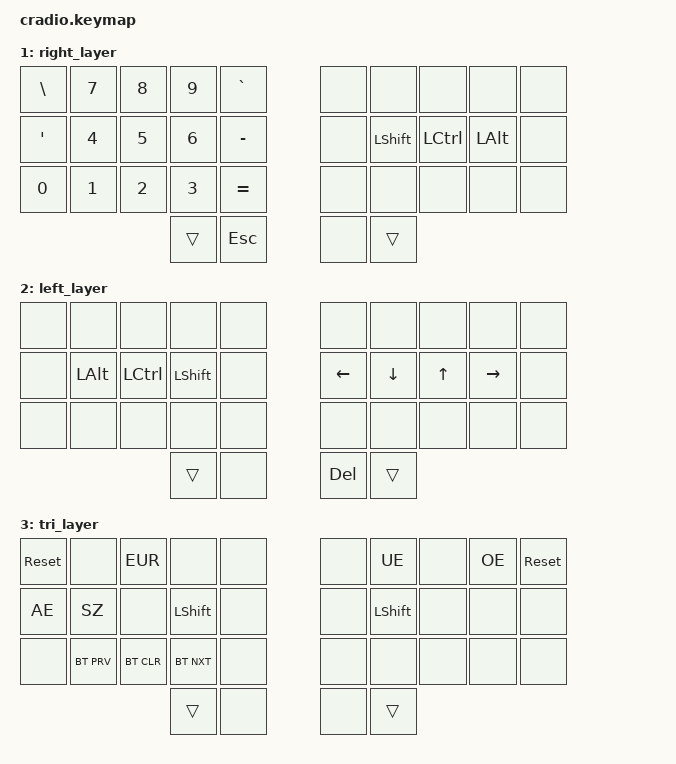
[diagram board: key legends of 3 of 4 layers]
// Copyright (c) 2022 The ZMK Contributors
// SPDX-License-Identifier: MIT

#include <behaviors.dtsi>
#include <dt-bindings/zmk/keys.h>
#include <dt-bindings/zmk/bt.h>

// Home row mods macro
#define HRML(k1,k2,k3) &ht_bl LALT  k1  &ht_bl LCTRL k2  &ht_bl LSHFT k3
#define HRMR(k1,k2,k3) &ht_bl LSHFT k1  &ht_bl LCTRL k2  &ht_bl LALT  k3

#define AE  RA(Q)
#define OE  RA(P)
#define UE  RA(Y)
#define SZ  RA(S)
#define EUR RA(N5)

/ {
    behaviors {
        ht_bl: hold_tap__hold_preferred {
            label = "hold_tap";
            compatible = "zmk,behavior-hold-tap";
            #binding-cells = <2>;
            flavor = "balanced";
            tapping-term-ms = <200>;
            quick-tap-ms = <150>;
            require-prior-idle-ms = <100>;
            bindings = <&kp>, <&kp>;
        };
    };

    combos {
        compatible = "zmk,combos";
        combo_lbrc {
            timeout-ms = <50>;
            key-positions = <10 11>;
            bindings = <&kp LBRC>;
        };
        combo_lbkt {
            timeout-ms = <50>;
            key-positions = <11 12>;
            bindings = <&kp LBKT>;
        };
        combo_lpar {
            timeout-ms = <50>;
            key-positions = <12 13>;
            bindings = <&kp LPAR>;
        };
        combo_rpar {
            timeout-ms = <50>;
            key-positions = <16 17>;
            bindings = <&kp RPAR>;
        };
        combo_rbkt {
            timeout-ms = <50>;
            key-positions = <17 18>;
            bindings = <&kp RBKT>;
        };
        combo_rbrc {
            timeout-ms = <50>;
            key-positions = <18 19>;
            bindings = <&kp RBRC>;
        };
    };

    conditional_layers {
        compatible = "zmk,conditional-layers";
        tri_layer {
            if-layers = <1 2>;
            then-layer = <3>;
        };
    };

    keymap {
        compatible = "zmk,keymap";
        default_layer {
            bindings = <
        //╭──────────┬──────────┬──────────┬──────────┬──────────╮   ╭──────────┬──────────┬──────────┬──────────┬──────────╮
        //│  Q       │  W       │  E       │  R       │  T       │   │  Y       │  U       │  I       │  O       │  P       │
            &kp Q      &kp W      &kp E      &kp R      &kp T          &kp Y      &kp U      &kp I      &kp O      &kp P
        //├──────────┼──────────┼──────────┼──────────┼──────────┤   ├──────────┼──────────┼──────────┼──────────┼──────────┤
        //│  A       │  S       │  D       │  F       │  G       │   │  H       │  J       │  K       │  L       │  ;:      │
            &kp A      HRML(S,    D,         F)         &kp G          &kp H      HRMR(J,    K,         L)         &kp SEMI
        //├──────────┼──────────┼──────────┼──────────┼──────────┤   ├──────────┼──────────┼──────────┼──────────┼──────────┤
        //│  Z       │  X       │  C       │  V       │  B       │   │  N       │  M       │ , <      │ . >      │ / ?      │
            &kp Z      &kp X      &kp C      &kp V      &kp B          &kp N      &kp M      &kp COMMA  &kp DOT    &kp FSLH
        //╰──────────┴──────────┴──────────┼──────────┼──────────┤   ├──────────┼──────────┼──────────┴──────────┴──────────╯
                                             &lt 2 TAB  &kp SPACE      &kp BSPC   &lt 1 ENTER
        //                                 ╰──────────┴──────────╯   ╰──────────┴──────────╯
            >;
        };

        right_layer {
            bindings = <
        //╭──────────┬──────────┬──────────┬──────────┬──────────╮   ╭──────────┬──────────┬──────────┬──────────┬──────────╮
        //│  \|      │  7       │  8       │  9       │  `~      │   │          │          │          │          │          │
            &kp BSLH   &kp N7     &kp N8     &kp N9     &kp GRAVE      &none      &none      &none      &none      &none
        //├──────────┼──────────┼──────────┼──────────┼──────────┤   ├──────────┼──────────┼──────────┼──────────┼──────────┤
        //│  '"      │  4       │  5       │  6       │  -_      │   │          │          │          │          │          │
            &kp SQT    &kp N4     &kp N5     &kp N6     &kp MINUS      &none      &kp LSHFT  &kp LCTRL  &kp LALT   &none
        //├──────────┼──────────┼──────────┼──────────┼──────────┤   ├──────────┼──────────┼──────────┼──────────┼──────────┤
        //│  0       │  1       │  2       │  3       │  =+      │   │          │          │          │          │          │
            &kp N0     &kp N1     &kp N2     &kp N3     &kp EQUAL      &none      &none      &none      &none      &none
        //╰──────────┴──────────┴──────────┼──────────┼──────────┤   ├──────────┼──────────┼──────────┴──────────┴──────────╯
                                             &trans     &kp ESC        &none      &trans
        //                                 ╰──────────┴──────────╯   ╰──────────┴──────────╯
            >;
        };

        left_layer {
            bindings = <
        //╭──────────┬──────────┬──────────┬──────────┬──────────╮   ╭──────────┬──────────┬──────────┬──────────┬──────────╮
        //│          │          │          │          │          │   │          │          │          │          │          │
            &none      &none      &none      &none      &none          &none      &none      &none      &none      &none
        //├──────────┼──────────┼──────────┼──────────┼──────────┤   ├──────────┼──────────┼──────────┼──────────┼──────────┤
        //│          │          │          │          │          │   │  LEFT    │  DOWN    │  UP      │  RIGHT   │          │
            &none      &kp LALT   &kp LCTRL  &kp LSHFT  &none          &kp LEFT   &kp DOWN   &kp UP     &kp RIGHT  &none
        //├──────────┼──────────┼──────────┼──────────┼──────────┤   ├──────────┼──────────┼──────────┼──────────┼──────────┤
        //│          │          │          │          │          │   │          │          │          │          │          │
            &none      &none      &none      &none      &none          &none      &none      &none      &none      &none
        //╰──────────┴──────────┴──────────┼──────────┼──────────┤   ├──────────┼──────────┼──────────┴──────────┴──────────╯
                                             &trans     &none          &kp DEL    &trans
        //                                 ╰──────────┴──────────╯   ╰──────────┴──────────╯
            >;
        };

        tri_layer {
            bindings = <
        //╭──────────┬──────────┬──────────┬──────────┬──────────╮   ╭──────────┬──────────┬──────────┬──────────┬──────────╮
        //│  RESET   │          │  EUR     │          │          │   │          │  UE      │          │  OE      │  RESET   │
           &sys_reset  &none      &kp EUR    &none      &none          &none      &kp UE     &none      &kp OE     &sys_reset
        //├──────────┼──────────┼──────────┼──────────┼──────────┤   ├──────────┼──────────┼──────────┼──────────┼──────────┤
        //│  AE      │  SZ      │          │          │          │   │          │          │          │          │          │
            &kp AE     &kp SZ     &none      &kp LSHFT  &none          &none      &kp LSHFT  &none      &none      &none
        //├──────────┼──────────┼──────────┼──────────┼──────────┤   ├──────────┼──────────┼──────────┼──────────┼──────────┤
        //│          │  BT PRV  │  BT CLR  │  BT NXT  │          │   │          │          │          │          │          │
            &none     &bt BT_PRV &bt BT_CLR &bt BT_NXT  &none          &none      &none      &none      &none      &none
        //╰──────────┴──────────┴──────────┼──────────┼──────────┤   ├──────────┼──────────┼──────────┴──────────┴──────────╯
                                             &trans     &none          &none      &trans
        //                                 ╰──────────┴──────────╯   ╰──────────┴──────────╯
            >;
        };
    };
};
